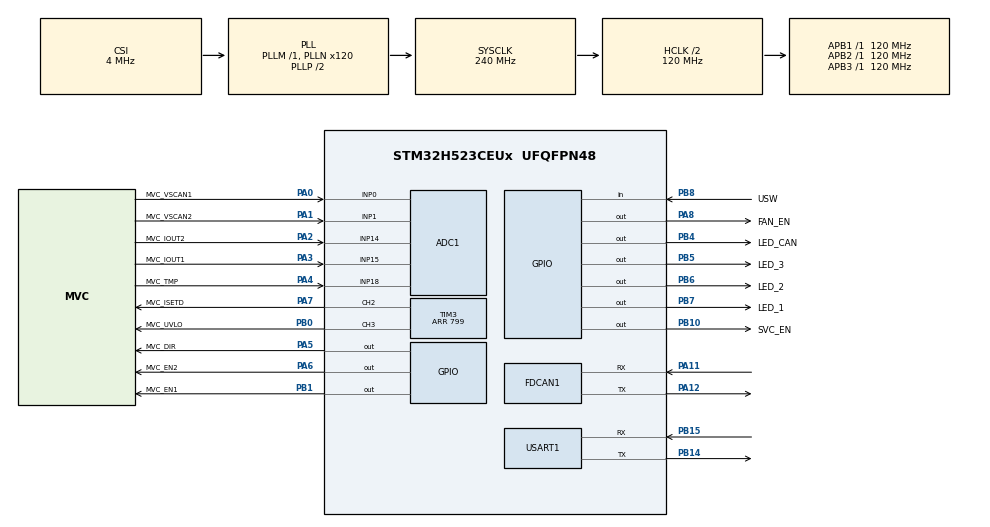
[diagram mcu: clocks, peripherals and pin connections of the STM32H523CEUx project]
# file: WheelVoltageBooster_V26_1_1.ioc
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ADC1.Channel-10\#ChannelRegularConversion=ADC_CHANNEL_18
ADC1.Channel-2\#ChannelRegularConversion=ADC_CHANNEL_0
ADC1.Channel-7\#ChannelRegularConversion=ADC_CHANNEL_1
ADC1.Channel-8\#ChannelRegularConversion=ADC_CHANNEL_14
ADC1.Channel-9\#ChannelRegularConversion=ADC_CHANNEL_15
ADC1.ClockPrescaler=ADC_CLOCK_ASYNC_DIV4
ADC1.ContinuousConvMode=ENABLE
ADC1.DMAContinuousRequests=ENABLE
ADC1.EOCSelection=ADC_EOC_SEQ_CONV
ADC1.EnableAnalogWatchDog1=false
ADC1.EnableInjectedConversion=DISABLE
ADC1.LowPowerAutoWait=DISABLE
ADC1.MonitoredBy-10\#ChannelRegularConversion=__NULL
ADC1.MonitoredBy-2\#ChannelRegularConversion=__NULL
ADC1.MonitoredBy-7\#ChannelRegularConversion=__NULL
ADC1.MonitoredBy-8\#ChannelRegularConversion=__NULL
ADC1.MonitoredBy-9\#ChannelRegularConversion=__NULL
ADC1.NbrOfConversion=5
ADC1.NbrOfConversionFlag=1
ADC1.OffsetNumber-10\#ChannelRegularConversion=ADC_OFFSET_NONE
ADC1.OffsetNumber-2\#ChannelRegularConversion=ADC_OFFSET_NONE
ADC1.OffsetNumber-7\#ChannelRegularConversion=ADC_OFFSET_NONE
ADC1.OffsetNumber-8\#ChannelRegularConversion=ADC_OFFSET_NONE
ADC1.OffsetNumber-9\#ChannelRegularConversion=ADC_OFFSET_NONE
ADC1.Overrun=ADC_OVR_DATA_OVERWRITTEN
ADC1.Rank-10\#ChannelRegularConversion=5
ADC1.Rank-2\#ChannelRegularConversion=1
ADC1.Rank-7\#ChannelRegularConversion=2
ADC1.Rank-8\#ChannelRegularConversion=3
ADC1.Rank-9\#ChannelRegularConversion=4
ADC1.SamplingTime-10\#ChannelRegularConversion=ADC_SAMPLETIME_24CYCLES_5
ADC1.SamplingTime-2\#ChannelRegularConversion=ADC_SAMPLETIME_24CYCLES_5
ADC1.SamplingTime-7\#ChannelRegularConversion=ADC_SAMPLETIME_24CYCLES_5
ADC1.SamplingTime-8\#ChannelRegularConversion=ADC_SAMPLETIME_24CYCLES_5
ADC1.SamplingTime-9\#ChannelRegularConversion=ADC_SAMPLETIME_24CYCLES_5
ADC1.master=1
BOOTPATH.BootPathName=LEGACY
BOOTPATH.UserSelectedBootPath=LEGACY
CORTEX_M33_NS.userName=CORTEX_M33
FDCAN1.CalculateBaudRateNominal=333333
FDCAN1.CalculateTimeBitNominal=3000
FDCAN1.CalculateTimeQuantumNominal=1000.0
GPDMA1.CIRCULARMODE_GPDMACH5=ENABLE
GPDMA1.DESTDATAWIDTH_GPDMACH5=DMA_DEST_DATAWIDTH_HALFWORD
GPDMA1.DESTINC_GPDMACH5=DMA_DINC_INCREMENTED
GPDMA1.IPHANDLE_GPDMACH5-SIMPLEREQUEST_GPDMACH5=__NULL
GPDMA1.REQUEST_GPDMACH5=GPDMA1_REQUEST_ADC1
GPDMA1.SRCDATAWIDTH_GPDMACH5=DMA_SRC_DATAWIDTH_HALFWORD
GPDMA1.TRANSFERALLOCATEDPORTDEST_GPDMACH5=DMA_DEST_ALLOCATED_PORT1
Mcu.Family=STM32H5
Mcu.Name=STM32H523CEUx
Mcu.Package=UFQFPN48
NVIC.GPDMA1_Channel5_IRQn=true\:0\:0\:false\:false\:true\:false\:true\:true
NVIC.PriorityGroup=NVIC_PRIORITYGROUP_4
PA0.GPIO_Label=MVC_VSCAN1
PA0.GPIO_Mode=GPIO_MODE_ANALOG
PA0.GPIO_PuPd=GPIO_NOPULL
PA0.Signal=ADCx_INP0
PA1.GPIO_Label=MVC_VSCAN2
PA1.GPIO_Mode=GPIO_MODE_ANALOG
PA1.GPIO_PuPd=GPIO_NOPULL
PA1.Signal=ADCx_INP1
PA11.Mode=FDCAN_Activate
PA11.Signal=FDCAN1_RX
PA12.Mode=FDCAN_Activate
PA12.Signal=FDCAN1_TX
PA2.GPIO_Label=MVC_IOUT2
PA2.GPIO_Mode=GPIO_MODE_ANALOG
PA2.GPIO_PuPd=GPIO_NOPULL
PA2.Signal=ADCx_INP14
PA3.GPIO_Label=MVC_IOUT1
PA3.GPIO_Mode=GPIO_MODE_ANALOG
PA3.GPIO_PuPd=GPIO_NOPULL
PA3.Signal=ADCx_INP15
PA4.GPIO_Label=MVC_TMP
PA4.GPIO_Mode=GPIO_MODE_ANALOG
PA4.GPIO_PuPd=GPIO_NOPULL
PA4.Signal=ADCx_INP18
PA5.GPIO_Label=MVC_DIR
PA5.Signal=GPIO_Output
PA6.GPIO_Label=MVC_EN2
PA6.Signal=GPIO_Output
PA7.GPIO_Label=MVC_ISETD
PA7.Signal=S_TIM3_CH2
PA8.GPIO_Label=FAN_EN
PA8.Signal=GPIO_Output
PB0.GPIO_Label=MVC_UVLO
PB0.Signal=S_TIM3_CH3
PB1.GPIO_Label=MVC_EN1
PB1.Signal=GPIO_Output
PB10.GPIO_Label=SVC_EN
PB10.Signal=GPIO_Output
PB14.GPIO_Speed=GPIO_SPEED_FREQ_VERY_HIGH
PB14.Mode=Asynchronous
PB14.Signal=USART1_TX
PB15.GPIO_Speed=GPIO_SPEED_FREQ_VERY_HIGH
PB15.Mode=Asynchronous
PB15.Signal=USART1_RX
PB4(NJTRST).GPIO_Label=LED_CAN
PB4(NJTRST).Signal=GPIO_Output
PB5.GPIO_Label=LED_3
PB5.Signal=GPIO_Output
PB6.GPIO_Label=LED_2
PB6.Signal=GPIO_Output
PB7.GPIO_Label=LED_1
PB7.Signal=GPIO_Output
PB8.GPIO_Label=USW
PB8.Signal=GPIO_Input
PH0-OSC_IN(PH0).Mode=HSE-External-Oscillator
PH0-OSC_IN(PH0).Signal=RCC_OSC_IN
PH1-OSC_OUT(PH1).Mode=HSE-External-Oscillator
PH1-OSC_OUT(PH1).Signal=RCC_OSC_OUT
ProjectManager.HeapSize=0x200
ProjectManager.StackSize=0x400
ProjectManager.TargetToolchain=Makefile
RCC.ADCFreq_Value=120000000
RCC.AHBCLKDivider=RCC_SYSCLK_DIV2
RCC.AHBFreq_Value=120000000
RCC.APB1Freq_Value=120000000
RCC.APB1TimFreq_Value=120000000
RCC.APB2Freq_Value=120000000
RCC.APB2TimFreq_Value=120000000
RCC.APB3Freq_Value=120000000
RCC.CSI_VALUE=4000000
RCC.CortexFreq_Value=120000000
RCC.EPOD_VALUE=4000000
RCC.HCLKFreq_Value=120000000
RCC.HSE_VALUE=16000000
RCC.HSI48_VALUE=48000000
RCC.HSI_VALUE=64000000
RCC.LSE_VALUE=32768
RCC.LSIRC_VALUE=32000
RCC.PLL2FRACN=0
RCC.PLL2N=120
RCC.PLL3FRACN=0
RCC.PLL3N=120
RCC.PLLFRACN=0
RCC.PLLN=120
RCC.SYSCLKFreq_VALUE=240000000
RCC.SYSCLKSource=RCC_SYSCLKSOURCE_PLLCLK
RCC.USBFreq_Value=48000000
RCC.VCOOutputFreq_Value=480000000
SH.ADCx_INP0.0=ADC1_INP0,IN0-Single-Ended
SH.ADCx_INP1.0=ADC1_INP1,IN1-Single-Ended
SH.ADCx_INP14.0=ADC1_INP14,IN14-Single-Ended
SH.ADCx_INP15.0=ADC1_INP15,IN15-Single-Ended
SH.ADCx_INP18.0=ADC1_INP18,IN18-Single-Ended
SH.S_TIM3_CH2.0=TIM3_CH2,PWM Generation2 CH2
SH.S_TIM3_CH3.0=TIM3_CH3,PWM Generation3 CH3
TIM3.Channel-PWM\ Generation2\ CH2=TIM_CHANNEL_2
TIM3.Channel-PWM\ Generation3\ CH3=TIM_CHANNEL_3
TIM3.OCFastMode_PWM-PWM\ Generation2\ CH2=TIM_OCFAST_ENABLE
TIM3.OCFastMode_PWM-PWM\ Generation3\ CH3=TIM_OCFAST_ENABLE
TIM3.PeriodNoDither=799
USART1.VirtualMode-Asynchronous=VM_ASYNC
VP_BOOTPATH_VS_BOOTPATH.Mode=BP_Activate
VP_CORTEX_M33_NS_VS_Hclk.Mode=Hclk_Mode
VP_GPDMA1_VS_GPDMACH5.Mode=SIMPLEREQUEST_GPDMACH5
VP_ICACHE_VS_ICACHE.Mode=DirectMappedCache
VP_MEMORYMAP_VS_MEMORYMAP.Mode=CurAppReg
VP_PWR_VS_DBSignals.Mode=DisableDeadBatterySignals
VP_PWR_VS_LPOM.Mode=PowerOptimisation
VP_PWR_VS_SECSignals.Mode=Security/Privilege
VP_TIM3_VS_ClockSourceINT.Mode=Internal
board=custom

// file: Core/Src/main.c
/* USER CODE BEGIN Header */
/**
  ******************************************************************************
  * @file           : main.c
  * @brief          : Main program body
  ******************************************************************************
  * @attention
  *
  * Copyright (c) 2025 STMicroelectronics.
  * All rights reserved.
  *
  * This software is licensed under terms that can be found in the LICENSE file
  * in the root directory of this software component.
  * If no LICENSE file comes with this software, it is provided AS-IS.
  *
  ******************************************************************************
  */
/* USER CODE END Header */
#include "main.h"

/* USER CODE BEGIN Includes */
#include "stdio.h"
#include "app.hpp"
/* USER CODE END Includes */

ADC_HandleTypeDef hadc1;
DMA_NodeTypeDef Node_GPDMA1_Channel5;
DMA_QListTypeDef List_GPDMA1_Channel5;
DMA_HandleTypeDef handle_GPDMA1_Channel5;

FDCAN_HandleTypeDef hfdcan1;

TIM_HandleTypeDef htim3;

UART_HandleTypeDef huart1;

void SystemClock_Config(void);
static void MX_GPIO_Init(void);
static void MX_GPDMA1_Init(void);
static void MX_FDCAN1_Init(void);
static void MX_USART1_UART_Init(void);
static void MX_TIM3_Init(void);
static void MX_ADC1_Init(void);
static void MX_ICACHE_Init(void);

/* USER CODE BEGIN 0 */
int _write(int file,char* ptr,int len){
  HAL_UART_Transmit(&huart1,(uint8_t*)ptr,len,100);
  return len;
}

/* USER CODE END 0 */

int main(void)
{

  /* MCU Configuration--------------------------------------------------------*/

  /* Reset of all peripherals, Initializes the Flash interface and the Systick. */
  HAL_Init();

  /* Configure the system clock */
  SystemClock_Config();

  /* Initialize all configured peripherals */
  MX_GPIO_Init();
  MX_GPDMA1_Init();
  MX_FDCAN1_Init();
  MX_USART1_UART_Init();
  MX_TIM3_Init();
  MX_ADC1_Init();
  MX_ICACHE_Init();
  /* USER CODE BEGIN 2 */
  HAL_TIM_PWM_Start(&htim3, TIM_CHANNEL_2);
  HAL_TIM_PWM_Start(&htim3, TIM_CHANNEL_3);

  Setup();
  /* USER CODE END 2 */

  /* Infinite loop */
  /* USER CODE BEGIN WHILE */
  while (1)
  {
    MainLoop();
    /* USER CODE END WHILE */

  }
}

void SystemClock_Config(void)
{
  RCC_OscInitTypeDef RCC_OscInitStruct = {0};
  RCC_ClkInitTypeDef RCC_ClkInitStruct = {0};

  /** Configure the main internal regulator output voltage
  */
  __HAL_PWR_VOLTAGESCALING_CONFIG(PWR_REGULATOR_VOLTAGE_SCALE0);

  while(!__HAL_PWR_GET_FLAG(PWR_FLAG_VOSRDY)) {}

  /** Initializes the RCC Oscillators according to the specified parameters
  * in the RCC_OscInitTypeDef structure.
  */
  RCC_OscInitStruct.OscillatorType = RCC_OSCILLATORTYPE_HSE|RCC_OSCILLATORTYPE_CSI;
  RCC_OscInitStruct.HSEState = RCC_HSE_ON;
  RCC_OscInitStruct.CSIState = RCC_CSI_ON;
  RCC_OscInitStruct.CSICalibrationValue = RCC_CSICALIBRATION_DEFAULT;
  RCC_OscInitStruct.PLL.PLLState = RCC_PLL_ON;
  RCC_OscInitStruct.PLL.PLLSource = RCC_PLL1_SOURCE_CSI;
  RCC_OscInitStruct.PLL.PLLM = 1;
  RCC_OscInitStruct.PLL.PLLN = 120;
  RCC_OscInitStruct.PLL.PLLP = 2;
  RCC_OscInitStruct.PLL.PLLQ = 2;
  RCC_OscInitStruct.PLL.PLLR = 2;
  RCC_OscInitStruct.PLL.PLLRGE = RCC_PLL1_VCIRANGE_2;
  RCC_OscInitStruct.PLL.PLLVCOSEL = RCC_PLL1_VCORANGE_WIDE;
  RCC_OscInitStruct.PLL.PLLFRACN = 0;
  if (HAL_RCC_OscConfig(&RCC_OscInitStruct) != HAL_OK)
  {
    Error_Handler();
  }

  /** Initializes the CPU, AHB and APB buses clocks
  */
  RCC_ClkInitStruct.ClockType = RCC_CLOCKTYPE_HCLK|RCC_CLOCKTYPE_SYSCLK
                              |RCC_CLOCKTYPE_PCLK1|RCC_CLOCKTYPE_PCLK2
                              |RCC_CLOCKTYPE_PCLK3;
  RCC_ClkInitStruct.SYSCLKSource = RCC_SYSCLKSOURCE_PLLCLK;
  RCC_ClkInitStruct.AHBCLKDivider = RCC_SYSCLK_DIV2;
  RCC_ClkInitStruct.APB1CLKDivider = RCC_HCLK_DIV1;
  RCC_ClkInitStruct.APB2CLKDivider = RCC_HCLK_DIV1;
  RCC_ClkInitStruct.APB3CLKDivider = RCC_HCLK_DIV1;

  if (HAL_RCC_ClockConfig(&RCC_ClkInitStruct, FLASH_LATENCY_5) != HAL_OK)
  {
    Error_Handler();
  }

  /** Configure the programming delay
  */
  __HAL_FLASH_SET_PROGRAM_DELAY(FLASH_PROGRAMMING_DELAY_2);
}

static void MX_ADC1_Init(void)
{

  ADC_ChannelConfTypeDef sConfig = {0};

  /** Common config
  */
  hadc1.Instance = ADC1;
  hadc1.Init.ClockPrescaler = ADC_CLOCK_ASYNC_DIV4;
  hadc1.Init.Resolution = ADC_RESOLUTION_12B;
  hadc1.Init.DataAlign = ADC_DATAALIGN_RIGHT;
  hadc1.Init.ScanConvMode = ADC_SCAN_ENABLE;
  hadc1.Init.EOCSelection = ADC_EOC_SEQ_CONV;
  hadc1.Init.LowPowerAutoWait = DISABLE;
  hadc1.Init.ContinuousConvMode = ENABLE;
  hadc1.Init.NbrOfConversion = 5;
  hadc1.Init.DiscontinuousConvMode = DISABLE;
  hadc1.Init.ExternalTrigConv = ADC_SOFTWARE_START;
  hadc1.Init.ExternalTrigConvEdge = ADC_EXTERNALTRIGCONVEDGE_NONE;
  hadc1.Init.DMAContinuousRequests = ENABLE;
  hadc1.Init.SamplingMode = ADC_SAMPLING_MODE_NORMAL;
  hadc1.Init.Overrun = ADC_OVR_DATA_OVERWRITTEN;
  hadc1.Init.OversamplingMode = DISABLE;
  if (HAL_ADC_Init(&hadc1) != HAL_OK)
  {
    Error_Handler();
  }

  /** Configure Regular Channel
  */
  sConfig.Channel = ADC_CHANNEL_0;
  sConfig.Rank = ADC_REGULAR_RANK_1;
  sConfig.SamplingTime = ADC_SAMPLETIME_24CYCLES_5;
  sConfig.SingleDiff = ADC_SINGLE_ENDED;
  sConfig.OffsetNumber = ADC_OFFSET_NONE;
  sConfig.Offset = 0;
  if (HAL_ADC_ConfigChannel(&hadc1, &sConfig) != HAL_OK)
  {
    Error_Handler();
  }

  /** Configure Regular Channel
  */
  sConfig.Channel = ADC_CHANNEL_1;
  sConfig.Rank = ADC_REGULAR_RANK_2;
  if (HAL_ADC_ConfigChannel(&hadc1, &sConfig) != HAL_OK)
  {
    Error_Handler();
  }

  /** Configure Regular Channel
  */
  sConfig.Channel = ADC_CHANNEL_14;
  sConfig.Rank = ADC_REGULAR_RANK_3;
  if (HAL_ADC_ConfigChannel(&hadc1, &sConfig) != HAL_OK)
  {
    Error_Handler();
  }

  /** Configure Regular Channel
  */
  sConfig.Channel = ADC_CHANNEL_15;
  sConfig.Rank = ADC_REGULAR_RANK_4;
  if (HAL_ADC_ConfigChannel(&hadc1, &sConfig) != HAL_OK)
  {
    Error_Handler();
  }

  /** Configure Regular Channel
  */
  sConfig.Channel = ADC_CHANNEL_18;
  sConfig.Rank = ADC_REGULAR_RANK_5;
  if (HAL_ADC_ConfigChannel(&hadc1, &sConfig) != HAL_OK)
  {
    Error_Handler();
  }

}

static void MX_FDCAN1_Init(void)
{

  hfdcan1.Instance = FDCAN1;
  hfdcan1.Init.ClockDivider = FDCAN_CLOCK_DIV1;
  hfdcan1.Init.FrameFormat = FDCAN_FRAME_CLASSIC;
  hfdcan1.Init.Mode = FDCAN_MODE_NORMAL;
  hfdcan1.Init.AutoRetransmission = DISABLE;
  hfdcan1.Init.TransmitPause = DISABLE;
  hfdcan1.Init.ProtocolException = DISABLE;
  hfdcan1.Init.NominalPrescaler = 16;
  hfdcan1.Init.NominalSyncJumpWidth = 1;
  hfdcan1.Init.NominalTimeSeg1 = 1;
  hfdcan1.Init.NominalTimeSeg2 = 1;
  hfdcan1.Init.DataPrescaler = 1;
  hfdcan1.Init.DataSyncJumpWidth = 1;
  hfdcan1.Init.DataTimeSeg1 = 1;
  hfdcan1.Init.DataTimeSeg2 = 1;
  hfdcan1.Init.StdFiltersNbr = 0;
  hfdcan1.Init.ExtFiltersNbr = 0;
  hfdcan1.Init.TxFifoQueueMode = FDCAN_TX_FIFO_OPERATION;
  if (HAL_FDCAN_Init(&hfdcan1) != HAL_OK)
  {
    Error_Handler();
  }

}

static void MX_GPDMA1_Init(void)
{

  /* Peripheral clock enable */
  __HAL_RCC_GPDMA1_CLK_ENABLE();

  /* GPDMA1 interrupt Init */
    HAL_NVIC_SetPriority(GPDMA1_Channel5_IRQn, 0, 0);
    HAL_NVIC_EnableIRQ(GPDMA1_Channel5_IRQn);

}

static void MX_ICACHE_Init(void)
{

  /** Enable instruction cache in 1-way (direct mapped cache)
  */
  if (HAL_ICACHE_ConfigAssociativityMode(ICACHE_1WAY) != HAL_OK)
  {
    Error_Handler();
  }
  if (HAL_ICACHE_Enable() != HAL_OK)
  {
    Error_Handler();
  }

}

static void MX_TIM3_Init(void)
{

  TIM_ClockConfigTypeDef sClockSourceConfig = {0};
  TIM_MasterConfigTypeDef sMasterConfig = {0};
  TIM_OC_InitTypeDef sConfigOC = {0};

  htim3.Instance = TIM3;
  htim3.Init.Prescaler = 0;
  htim3.Init.CounterMode = TIM_COUNTERMODE_UP;
  htim3.Init.Period = 799;
  htim3.Init.ClockDivision = TIM_CLOCKDIVISION_DIV1;
  htim3.Init.AutoReloadPreload = TIM_AUTORELOAD_PRELOAD_DISABLE;
  if (HAL_TIM_Base_Init(&htim3) != HAL_OK)
  {
    Error_Handler();
  }
  sClockSourceConfig.ClockSource = TIM_CLOCKSOURCE_INTERNAL;
  if (HAL_TIM_ConfigClockSource(&htim3, &sClockSourceConfig) != HAL_OK)
  {
    Error_Handler();
  }
  if (HAL_TIM_PWM_Init(&htim3) != HAL_OK)
  {
    Error_Handler();
  }
  sMasterConfig.MasterOutputTrigger = TIM_TRGO_RESET;
  sMasterConfig.MasterSlaveMode = TIM_MASTERSLAVEMODE_DISABLE;
  if (HAL_TIMEx_MasterConfigSynchronization(&htim3, &sMasterConfig) != HAL_OK)
  {
    Error_Handler();
  }
  sConfigOC.OCMode = TIM_OCMODE_PWM1;
  sConfigOC.Pulse = 0;
  sConfigOC.OCPolarity = TIM_OCPOLARITY_HIGH;
  sConfigOC.OCFastMode = TIM_OCFAST_ENABLE;
  if (HAL_TIM_PWM_ConfigChannel(&htim3, &sConfigOC, TIM_CHANNEL_2) != HAL_OK)
  {
    Error_Handler();
  }
  if (HAL_TIM_PWM_ConfigChannel(&htim3, &sConfigOC, TIM_CHANNEL_3) != HAL_OK)
  {
    Error_Handler();
  }
  HAL_TIM_MspPostInit(&htim3);

}

static void MX_USART1_UART_Init(void)
{

  huart1.Instance = USART1;
  huart1.Init.BaudRate = 115200;
  huart1.Init.WordLength = UART_WORDLENGTH_8B;
  huart1.Init.StopBits = UART_STOPBITS_1;
  huart1.Init.Parity = UART_PARITY_NONE;
  huart1.Init.Mode = UART_MODE_TX_RX;
  huart1.Init.HwFlowCtl = UART_HWCONTROL_NONE;
  huart1.Init.OverSampling = UART_OVERSAMPLING_16;
  huart1.Init.OneBitSampling = UART_ONE_BIT_SAMPLE_DISABLE;
  huart1.Init.ClockPrescaler = UART_PRESCALER_DIV1;
  huart1.AdvancedInit.AdvFeatureInit = UART_ADVFEATURE_NO_INIT;
  if (HAL_UART_Init(&huart1) != HAL_OK)
  {
    Error_Handler();
  }
  if (HAL_UARTEx_SetTxFifoThreshold(&huart1, UART_TXFIFO_THRESHOLD_1_8) != HAL_OK)
  {
    Error_Handler();
  }
  if (HAL_UARTEx_SetRxFifoThreshold(&huart1, UART_RXFIFO_THRESHOLD_1_8) != HAL_OK)
  {
    Error_Handler();
  }
  if (HAL_UARTEx_DisableFifoMode(&huart1) != HAL_OK)
  {
    Error_Handler();
  }

}

static void MX_GPIO_Init(void)
{
  GPIO_InitTypeDef GPIO_InitStruct = {0};

  /* GPIO Ports Clock Enable */
  __HAL_RCC_GPIOH_CLK_ENABLE();
  __HAL_RCC_GPIOA_CLK_ENABLE();
  __HAL_RCC_GPIOB_CLK_ENABLE();

  /*Configure GPIO pin Output Level */
  HAL_GPIO_WritePin(GPIOA, MVC_DIR_Pin|MVC_EN2_Pin|FAN_EN_Pin, GPIO_PIN_RESET);

  /*Configure GPIO pin Output Level */
  HAL_GPIO_WritePin(GPIOB, MVC_EN1_Pin|SVC_EN_Pin|LED_CAN_Pin|LED_3_Pin
                          |LED_2_Pin|LED_1_Pin, GPIO_PIN_RESET);

  /*Configure GPIO pins : MVC_DIR_Pin MVC_EN2_Pin FAN_EN_Pin */
  GPIO_InitStruct.Pin = MVC_DIR_Pin|MVC_EN2_Pin|FAN_EN_Pin;
  GPIO_InitStruct.Mode = GPIO_MODE_OUTPUT_PP;
  GPIO_InitStruct.Pull = GPIO_NOPULL;
  GPIO_InitStruct.Speed = GPIO_SPEED_FREQ_LOW;
  HAL_GPIO_Init(GPIOA, &GPIO_InitStruct);

  /*Configure GPIO pins : MVC_EN1_Pin SVC_EN_Pin LED_CAN_Pin LED_3_Pin
                           LED_2_Pin LED_1_Pin */
  GPIO_InitStruct.Pin = MVC_EN1_Pin|SVC_EN_Pin|LED_CAN_Pin|LED_3_Pin
                          |LED_2_Pin|LED_1_Pin;
  GPIO_InitStruct.Mode = GPIO_MODE_OUTPUT_PP;
  GPIO_InitStruct.Pull = GPIO_NOPULL;
  GPIO_InitStruct.Speed = GPIO_SPEED_FREQ_LOW;
  HAL_GPIO_Init(GPIOB, &GPIO_InitStruct);

  /*Configure GPIO pin : USW_Pin */
  GPIO_InitStruct.Pin = USW_Pin;
  GPIO_InitStruct.Mode = GPIO_MODE_INPUT;
  GPIO_InitStruct.Pull = GPIO_NOPULL;
  HAL_GPIO_Init(USW_GPIO_Port, &GPIO_InitStruct);

}

void Error_Handler(void)
{
  __disable_irq();
  while (1)
  {
  }
}
